# MLDR187 register map
File version: 1.4
CPU: MDR32F02, little endian
Registers are 32-bit, read-write, no defined reset value unless marked. A register's access mark holds for its fields unless they carry their own. Offsets are from the block's base; [hi:lo] are bit positions; {n}, {i} and the like mark numbered series.

## OTP — OTP description
Base 0x70010000
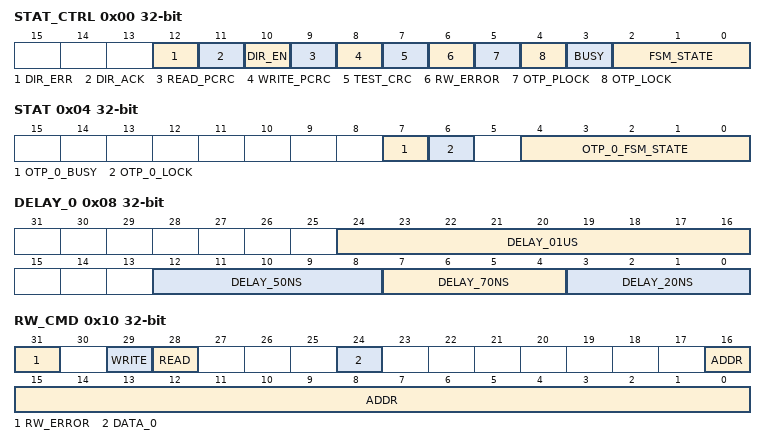
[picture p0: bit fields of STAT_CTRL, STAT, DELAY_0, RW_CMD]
0x00 STAT_CTRL — Status and control register
  [12] DIR_ERR — Oshibka vkljuchenija rezhima prjamogo upravlenija
  [11] DIR_ACK — Podtverzhdenie vkljuchenija rezhima prjamogo upravlenija
  [10] DIR_EN — Zapros rezhima prjamogo upravlenija
  [9] READ_PCRC — Sostojanie signala celostnosti dannyh registra zaszity ot chtenija
  [8] WRITE_PCRC — Sostojanie signala celostnosti dannyh registra zaszity ot zapisi
  [7] TEST_CRC — Sostojanie signala celostnosti dannyh special'nyh testovyh opcij
  [6] RW_ERROR — Oshibka chtenija ili zapisi
  [5] OTP_PLOCK — Signal chastichnoj blokirovki OTP ot zapisi, edinica v dannom signali oznachaet chto nekotorye banki modulja blokirovany
  [4] OTP_LOCK — Signal blokirovki OTP ot zapisi, edinica v dannom signali oznachaet chto vse banki modulja blokirovany
  [3] BUSY — OTP vypolnjaet kakie-libo dejstvija i ne gotovo prinjat' ocherednoj zapros na chtenie ili zapis'
  [2:0] FSM_STATE — Sostojanie konechnogo avtomata obszego kontrollera modulja
0x04 STAT — Blocks status register
  [7] OTP_0_BUSY — Modul' OTP 0 vypolnjaet kakie-libo dejstvija i ne gotovo prinjat' ocherednoj zapros na chtenie ili zapis'
  [6] OTP_0_LOCK — Sostojanie blokirovki zapisi modulja OTP 0
  [4:0] OTP_0_FSM_STATE — Sostojanie konechnogo avtomata bloka OTP
0x08 DELAY_0
  [24:16] DELAY_01US — Velichina zaderzhki zadaetsja v taktah osnovnoj chastoty raboty modulja, pauza ravna N+1 taktu, gde N zadannoe v pole chislo. I dolzhna byt' ne men'she 1mks ine bolee 2mks.
  [12:8] DELAY_50NS — Velichina zaderzhki zadaetsja v taktah osnovnoj chastoty raboty modulja, pauza ravna N+1 taktu, gde N zadannoe v pole chislo. I dolzhna byt' ne men'she 50ns.
  [7:4] DELAY_70NS — pri chtenii dannyh iz OTP po shine AHB. Velichina zaderzhki zadaetsja v taktah osnovnoj chastoty raboty modulja, pauza ravna N+1 taktu, gde N zadannoe v pole chislo. I dolzhna byt' ne men'she 70ns.
  [3:0] DELAY_20NS — Velichina zaderzhki zadaetsja v taktah osnovnoj chastoty raboty modulja, pauza ravna N+1 taktu, gde N zadannoe v pole chislo. I dolzhna byt' ne men'she 20ns.
0x0C DELAY_1
  [16:0] DELAY_16US — Velichina zaderzhki zadaetsja v taktah osnovnoj chastoty raboty modulja, pauza ravna N+1 taktu, gde N zadannoe v pole chislo. I dolzhna byt' ne men'she 16mks ine bol'she 17mks.
0x10 RW_CMD — Read/write command register
  [31] RW_ERROR — Oshibka vypolnenija poslednej operacii chtenija ili zapisi Oshibka voznikaet pri popytke chtenija ili zapisi vo vremja ustanovlennogo signala BUSY
  [29] WRITE — Komanda na zapis' v ukazannyj adres, pri nalichii 1 v dannom pole i 0 v pole komandy chtenija proizvodit'sja procedura zapisi.
  [28] READ — Komanda na chtenie iz ukazannogo adresa, pri nalichii 1 v dannom pole i 0 v pole komandy zapisi proizvodit'sja procedura chtenija.
  [24] DATA_0 — Dannye dlja zapisi v OTP 0 -ne proizvodit' zapis'.Nachal'noe sostojanie OTP - 0, zapisat' mozhno tol'ko 1, steret' 1 uzhe nel'zja
  [16:0] ADDR — Bitovyj adres zapisi i chtenija. Zapis' proizvodit'sja bitami, chtenie proizvodit'sja bajtami, pri chtenii mladshie 3 bita ignorirujutsja i schitajutsja ravnymi 0.
0x14 READ_DATA
  [7:0] DATA_0 — Dannye schitannye iz 0 banka OTP v sluchae uspeshnogo zavershenija procedury chtenija, pri oshibkah v pole zanosit'sja konstanta 0xEF
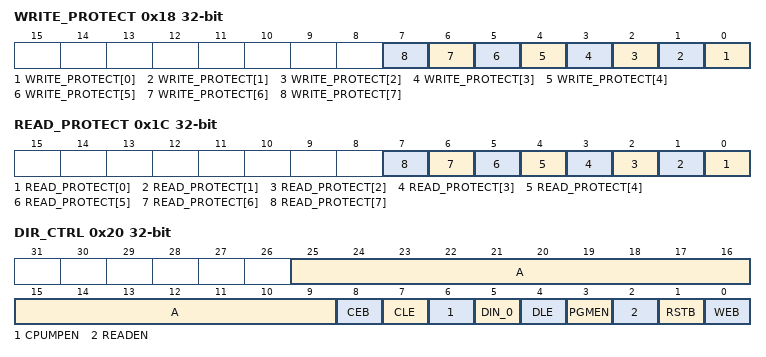
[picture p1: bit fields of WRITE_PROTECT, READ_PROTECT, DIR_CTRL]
0x18 WRITE_PROTECT — Write protection register
  [n] WRITE_PROTECT[{n}] (n=0..7)
0x1C READ_PROTECT — Read protection register
  [n] READ_PROTECT[{n}] (n=0..7)
0x20 DIR_CTRL — Direct control register
  [25:9] A, [8] CEB, [7] CLE, [6] CPUMPEN, [5] DIN_0, [4] DLE, [3] PGMEN, [2] READEN, [1] RSTB, [0] WEB
0x24 DIR_DATA — Direct control data register
  [7:0] D_0 — V rezhime prjamogo upravlenija soderzhit prochitannye dannye iz bloka OTP
0x28 TEST_OPT — Test options register
